# STM32H725 register map
File version: 2.0
CPU: CM7 r0p1, little endian, MPU, FPU, 4 interrupt priority bits
Registers are 32-bit, read-write, reset 0x0 unless marked. A register's access mark holds for its fields unless they carry their own. Offsets are from the block's base; [hi:lo] are bit positions; {n}, {i} and the like mark numbered series.

## DBGMCU — DBGMCU address block description
Base 0x5C001000
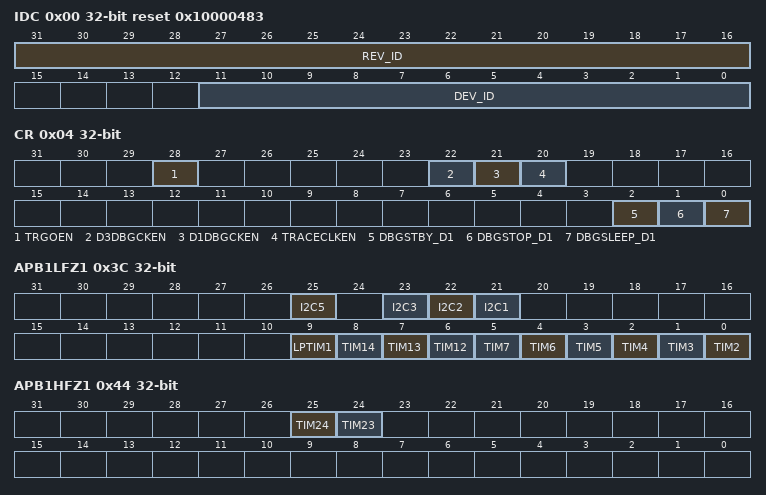
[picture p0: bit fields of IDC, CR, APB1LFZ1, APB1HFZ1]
0x00 IDC ro reset 0x10000483
  [31:16] REV_ID — Revision
  [11:0] DEV_ID — Device ID
0x04 CR
  [28] TRGOEN — External trigger output enable
  [22] D3DBGCKEN — D3 debug clock enable
  [21] D1DBGCKEN — D1 debug clock enable
  [20] TRACECLKEN — Trace port clock enable
  [2] DBGSTBY_D1 — D1 domain debug in Standby mode enable
  [1] DBGSTOP_D1 — D1 domain debug in Stop mode enable
  [0] DBGSLEEP_D1 — D1 domain debug in Sleep mode enable
0x34 APB3FZ1
  [6] WWDG1 — WWDG1 stop in debug
0x3C APB1LFZ1
  [25] I2C5 — I2C5 SMBUS timeout stop in debug
  [23] I2C3 — I2C3 SMBUS timeout stop in debug
  [22] I2C2 — I2C2 SMBUS timeout stop in debug
  [21] I2C1 — I2C1 SMBUS timeout stop in debug
  [9] LPTIM1 — LPTIM1 stop in debug
  [8] TIM14 — TIM14 stop in debug
  [7] TIM13 — TIM13 stop in debug
  [6] TIM12 — TIM12 stop in debug
  [n-2] TIM{n} (n=2..7) — TIM{n} stop in debug
0x44 APB1HFZ1
  [25] TIM24 — TIM24 stop in debug
  [24] TIM23 — TIM23 stop in debug
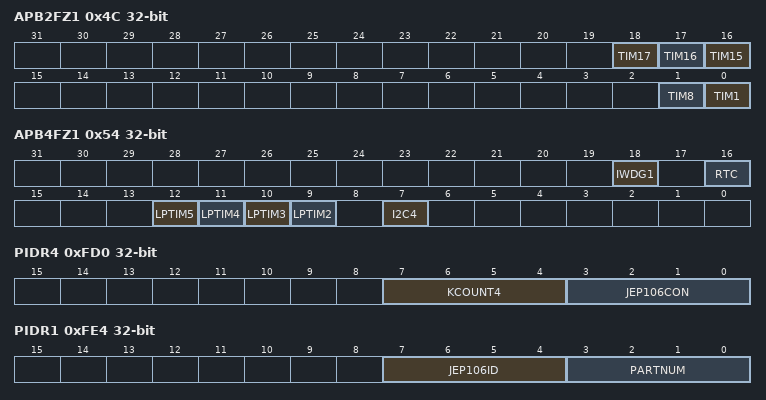
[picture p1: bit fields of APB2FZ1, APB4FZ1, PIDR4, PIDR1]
0x4C APB2FZ1
  [18] TIM17 — TIM17 stop in debug
  [17] TIM16 — TIM16 stop in debug
  [16] TIM15 — TIM15 stop in debug
  [1] TIM8 — TIM8 stop in debug
  [0] TIM1 — TIM1 stop in debug
0x54 APB4FZ1
  [18] IWDG1 — Independent watchdog for D1 stop in debug
  [16] RTC — RTC stop in debug
  [12] LPTIM5 — LPTIM5 stop in debug
  [11] LPTIM4 — LPTIM4 stop in debug
  [10] LPTIM3 — LPTIM2 stop in debug
  [9] LPTIM2 — LPTIM2 stop in debug
  [7] I2C4 — I2C4 SMBUS timeout stop in debug
0xFD0 PIDR4 ro
  [7:4] KCOUNT4 — Register file size
  [3:0] JEP106CON — JEP106 continuation code
0xFE0 PIDR0 ro
  [7:0] PARTNUM — Part number field, bits [7:0]
0xFE4 PIDR1 ro
  [7:4] JEP106ID — JEP106 identity code field, bits [3:0]
  [3:0] PARTNUM — Part number field, bits [11:8]
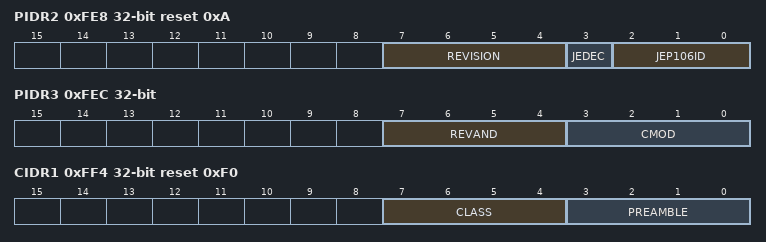
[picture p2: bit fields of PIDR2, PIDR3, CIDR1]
0xFE8 PIDR2 ro reset 0xA
  [7:4] REVISION — Component revision number
  [3] JEDEC — JEDEC assigned value
  [2:0] JEP106ID — JEP106 identity code field, bits [6:4]
0xFEC PIDR3 ro
  [7:4] REVAND — Metal fix version
  [3:0] CMOD — Customer modified
0xFF0 CIDR0 ro reset 0xD
  [7:0] PREAMBLE — Component ID field, bits [7:0]
0xFF4 CIDR1 ro reset 0xF0
  [7:4] CLASS — Component ID field, bits [15:12] - component class
  [3:0] PREAMBLE — Component ID field, bits [11:8]
0xFF8 CIDR2 ro reset 0x5
  [7:0] PREAMBLE — Component ID field, bits [23:16]
0xFFC CIDR3 ro reset 0xB1
  [7:0] PREAMBLE — Component ID field, bits [31:24]

## DELAY_Block_SDMMC1
Base 0x52008000
Same registers: DELAY_Block_SDMMC2 0x48022800, Delay_Block_OCTOSPI1 0x52006000, Delay_Block_OCTOSPI2 0x5200B000
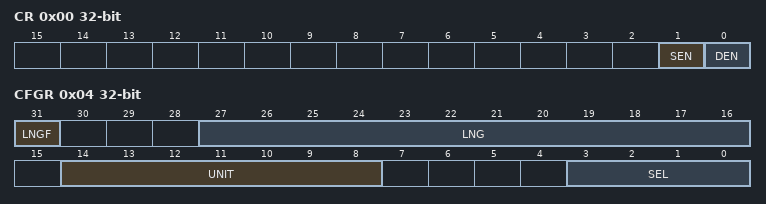
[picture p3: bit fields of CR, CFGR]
0x00 CR — DLYB control register
  [1] SEN — Sampler length enable bit
  [0] DEN — Delay block enable bit
0x04 CFGR — DLYB configuration register
  [31] LNGF — Length valid flag
  [27:16] LNG — Delay line length value
  [14:8] UNIT — Delay Defines the delay of a Unit delay cell
  [3:0] SEL — Select the phase for the Output clock

## Ethernet_MTL
Base 0x40028C00
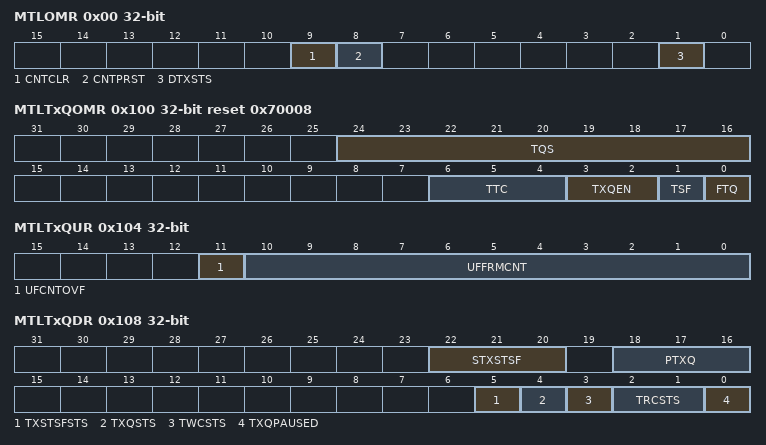
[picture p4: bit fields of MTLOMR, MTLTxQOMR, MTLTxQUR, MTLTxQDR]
0x00 MTLOMR access not given — Operating mode Register
  [9] CNTCLR — Counters Reset
  [8] CNTPRST — Counters Preset
  [1] DTXSTS — Drop Transmit Status
0x20 MTLISR access not given — Interrupt status Register
  [0] Q0IS — Queue interrupt status
0x100 MTLTxQOMR access not given reset 0x70008 — Tx queue operating mode Register
  [24:16] TQS — Transmit Queue Size
  [6:4] TTC — Transmit Threshold Control
  [3:2] TXQEN — Transmit Queue Enable
  [1] TSF — Transmit Store and Forward
  [0] FTQ — Flush Transmit Queue
0x104 MTLTxQUR access not given — Tx queue underflow register
  [11] UFCNTOVF — Overflow Bit for Underflow Packet Counter
  [10:0] UFFRMCNT — Underflow Packet Counter
0x108 MTLTxQDR access not given — Tx queue debug Register
  [22:20] STXSTSF — Number of Status Words in Tx Status FIFO of Queue
  [18:16] PTXQ — Number of Packets in the Transmit Queue
  [5] TXSTSFSTS — MTL Tx Status FIFO Full Status
  [4] TXQSTS — MTL Tx Queue Not Empty Status
  [3] TWCSTS — MTL Tx Queue Write Controller Status
  [2:1] TRCSTS — MTL Tx Queue Read Controller Status
  [0] TXQPAUSED — Transmit Queue in Pause
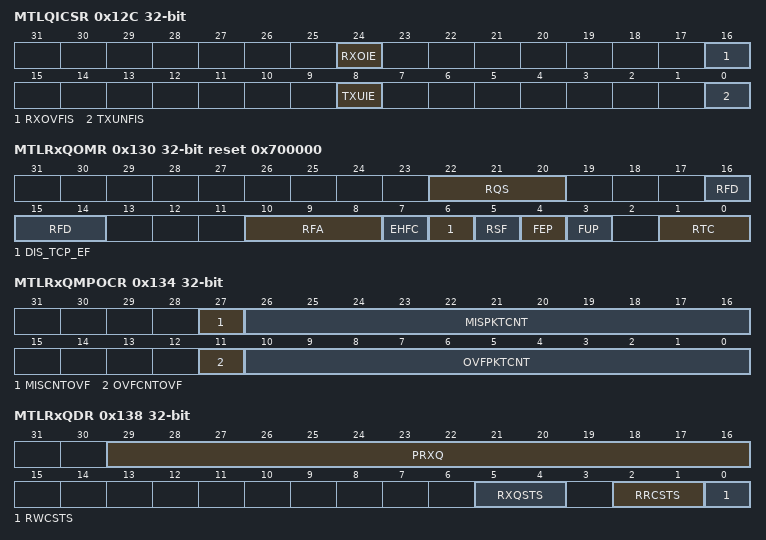
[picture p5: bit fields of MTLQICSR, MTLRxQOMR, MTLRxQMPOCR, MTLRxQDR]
0x12C MTLQICSR access not given — Queue interrupt control status Register
  [24] RXOIE — Receive Queue Overflow Interrupt Enable
  [16] RXOVFIS — Receive Queue Overflow Interrupt Status
  [8] TXUIE — Transmit Queue Underflow Interrupt Enable
  [0] TXUNFIS — Transmit Queue Underflow Interrupt Status
0x130 MTLRxQOMR access not given reset 0x700000 — Rx queue operating mode register
  [22:20] RQS — Receive Queue Size
  [16:14] RFD — Threshold for Deactivating Flow Control
  [10:8] RFA — Threshold for Activating Flow Control
  [7] EHFC — Enable Hardware Flow Control
  [6] DIS_TCP_EF — Disable Dropping of TCP
  [5] RSF — Receive Queue Store and Forward
  [4] FEP — Forward Error Packets
  [3] FUP — Forward Undersized Good Packets
  [1:0] RTC — Receive Queue Threshold Control
0x134 MTLRxQMPOCR access not given — Rx queue missed packet and overflow counter register
  [27] MISCNTOVF — Missed Packet Counter Overflow Bit
  [26:16] MISPKTCNT — Missed Packet Counter
  [11] OVFCNTOVF — Overflow Counter Overflow Bit
  [10:0] OVFPKTCNT — Overflow Packet Counter
0x138 MTLRxQDR access not given — Rx queue debug register
  [29:16] PRXQ — Number of Packets in Receive Queue
  [5:4] RXQSTS — MTL Rx Queue Fill-Level Status
  [2:1] RRCSTS — MTL Rx Queue Read Controller State
  [0] RWCSTS — MTL Rx Queue Write Controller Active Status
